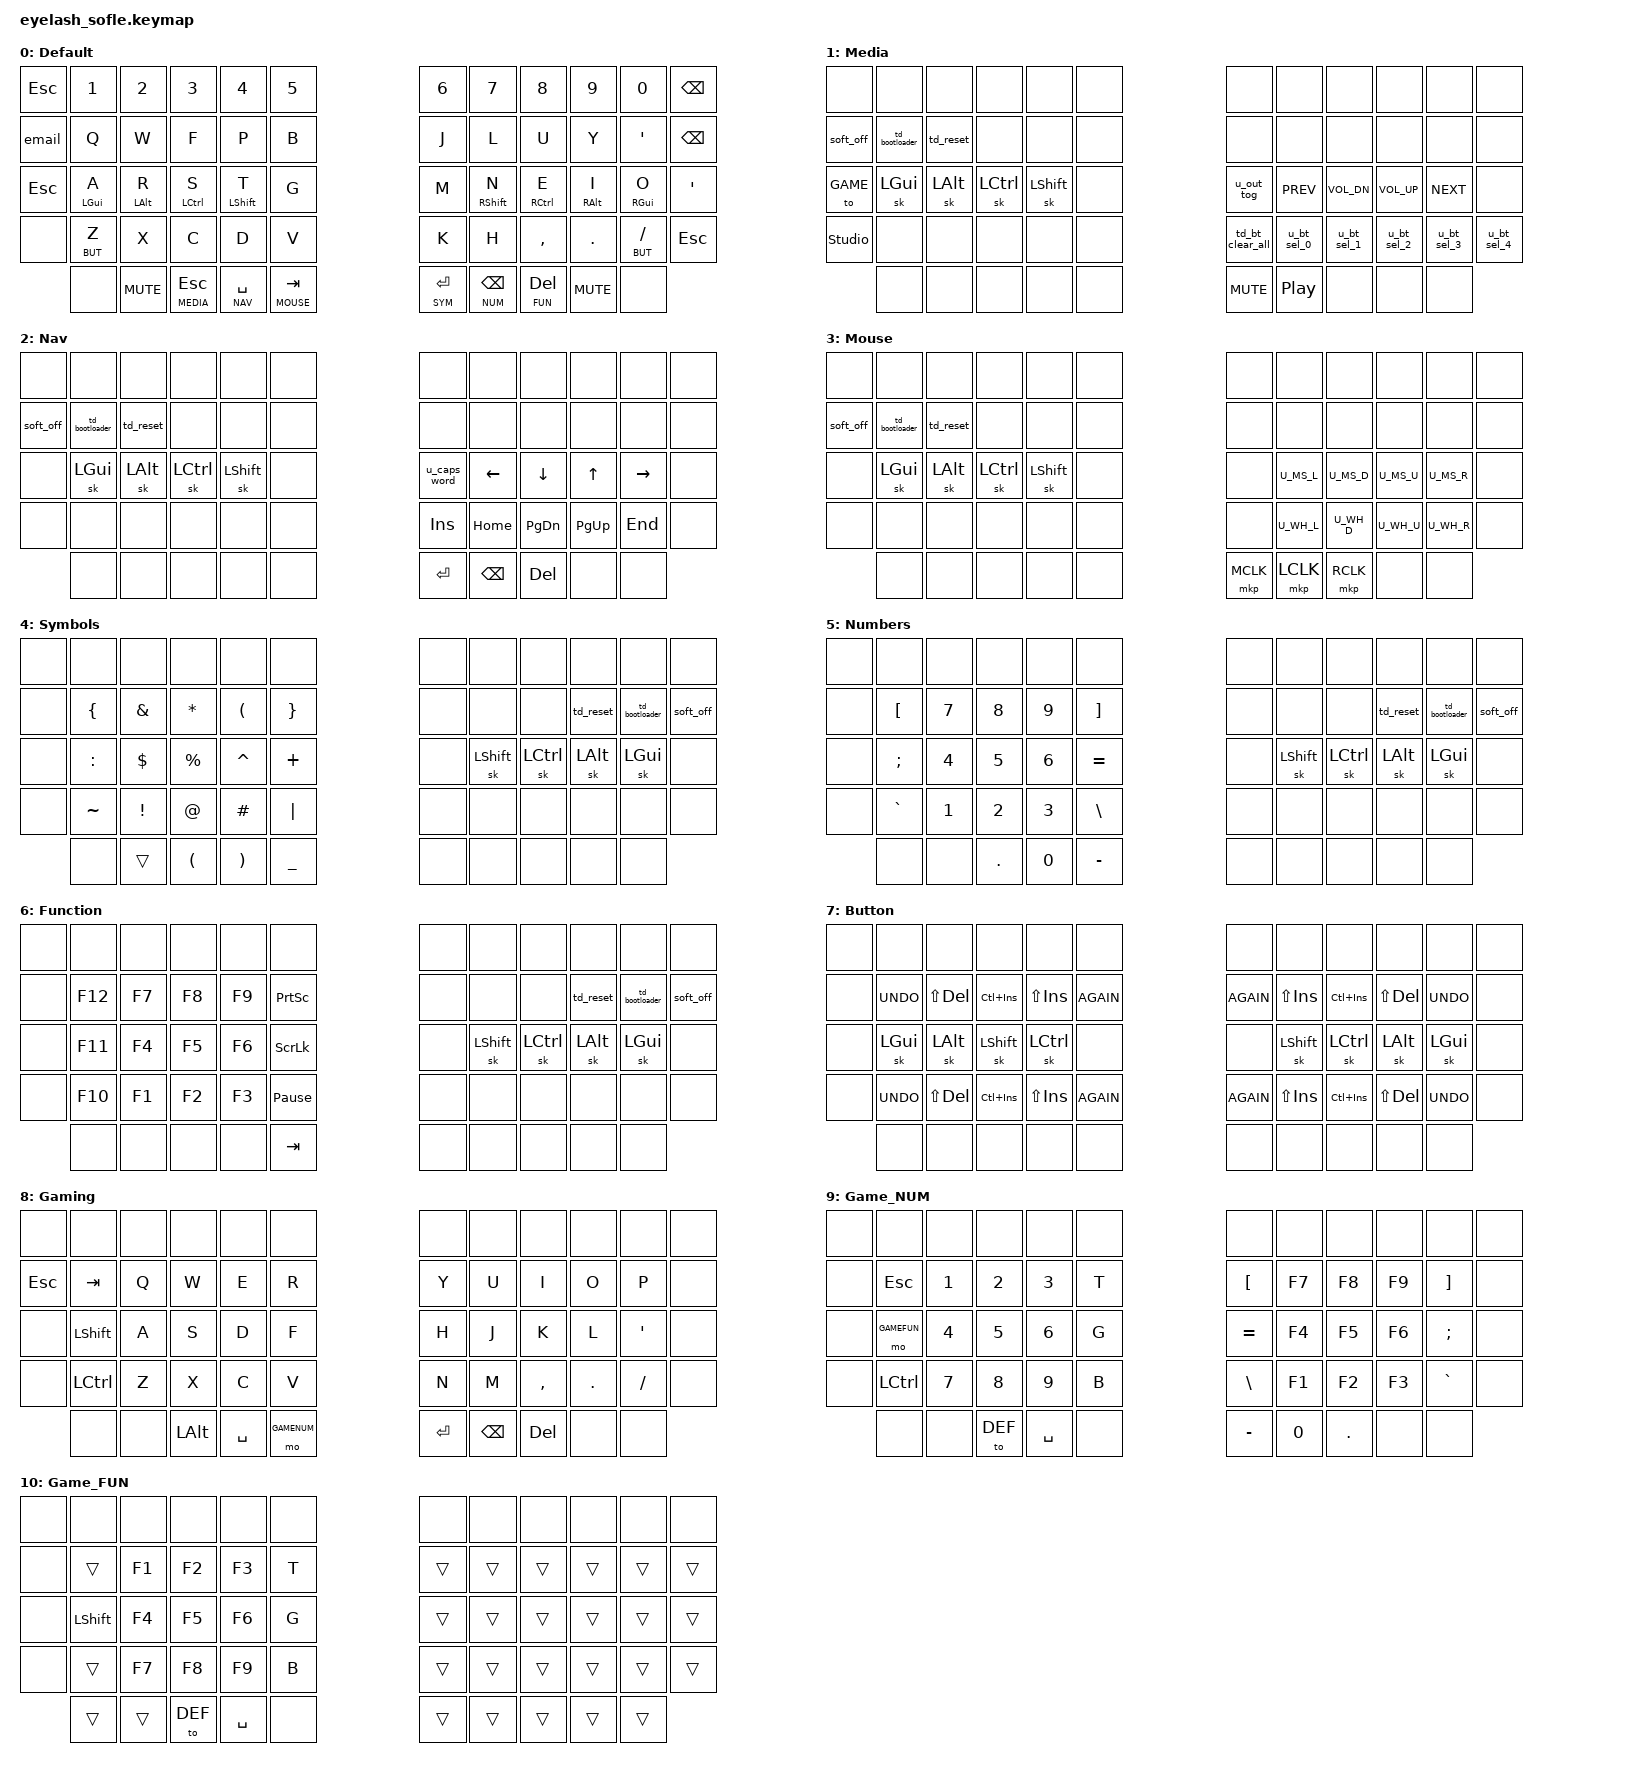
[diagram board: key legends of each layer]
//Personal keymap, subject to weird things, heavy use of helpers intended, and sticky keys

#include <behaviors.dtsi>
#include <dt-bindings/zmk/keys.h>
#include <dt-bindings/zmk/bt.h>
// #include <dt-bindings/zmk/outputs.h>

#include "zmk-helpers/helper.h"
#include "zmk-helpers/key-labels/sofle.h"
/*
  ╭────────────────────────────┬────────────────────────────╮ ╭─────────────────────────────┬─────────────────────────────╮
  │  0   1   2   3   4   5     │      6   7   8   9  10  11 │ │ LN5 LN4 LN3 LN2 LN1 LN0     │     RN0 RN1 RN2 RN3 RN4 RN5 │
  │ 12  13  14  15  16  17     │     18  19  20  21  22  23 │ │ LT5 LT4 LT3 LT2 LT1 LT0     │     RT0 RT1 RT2 RT3 RT4 RT5 │
  │ 24  25  26  27  28  29     │     30  31  32  33  34  35 │ │ LM5 LM4 LM3 LM2 LM1 LM0     │     RM0 RM1 RM2 RM3 RM4 RM5 │
  │ 36  37  38  39  40  41  42 │ 43  44  45  46  47  48  49 │ │ LB5 LB4 LB3 LB2 LB1 LB0 LEC │ REC RB0 RB1 RB2 RB3 RB4 RB5 │
  ╰───────╮ 50  51  52  53  54 │ 55  56  57  58  59 ╭───────╯ ╰───────╮ LH4 LH3 LH2 LH1 LH0 │ RH0 RH1 RH2 RH3 RH4 ╭───────╯
          ╰────────────────────┴────────────────────╯                 ╰─────────────────────┴─────────────────────╯         */

#define DEF 0
#define MEDIA 1
#define NAV 2
#define MOUSE 3
#define SYM 4
#define NUM 5
#define FUN 6
#define BUT 7
#define GAME 8
#define GAMENUM 9
#define GAMEFUN 10

#define XXX &none
#define ___ &trans

/* Global defaults */

#define QUICK_TAP_MS 175

&sk {
  release-after-ms = <900>;
  quick-release;
};

&sl { // Allow sticky mods to chord across sticky layers.
  ignore-modifiers;
};

&lt {
  flavor = "balanced";
  tapping-term-ms = <150>;
  quick-tap-ms = <QUICK_TAP_MS>;
};

#define KEYS_L LN0 LN1 LN2 LN3 LN4 LN5 LT0 LT1 LT2 LT3 LT4 LT5 LM0 LM1 LM2 LM3 LM4 LM5 LEC LB0 LB1 LB2 LB3 LB4 LB5
#define KEYS_R RN0 RN1 RN2 RN3 RN4 RN5 RT0 RT1 RT2 RT3 RT4 RT5 RM0 RM1 RM2 RM3 RM4 RM5 REC RB0 RB1 RB2 RB3 RB4 RB5
#define THUMBS LH4 LH3 LH2 LH1 LH0 RH0 RH1 RH2 RH3 RH4


/* Left-hand HRMs. */
ZMK_HOLD_TAP(hml,
    flavor = "balanced";
    tapping-term-ms = <170>;
    quick-tap-ms = <175>;
    require-prior-idle-ms = <90>;
    bindings = <&kp>, <&kp>;
    hold-trigger-key-positions = <KEYS_R THUMBS>;
    hold-trigger-on-release;
)

/* Right-hand HRMs. */
ZMK_HOLD_TAP(hmr,
    flavor = "balanced";
    tapping-term-ms = <170>;
    quick-tap-ms = <175>;
    require-prior-idle-ms = <90>;
    bindings = <&kp>, <&kp>;
    hold-trigger-key-positions = <KEYS_L THUMBS>;
    hold-trigger-on-release;
)
/* Combos, leader key sequences, mouse emulation */

// #include "combos.dtsi" // Must be sourced after HRM-combo hack.
// #include "leader.dtsi"
#include "mouse.dtsi"
#include "shift_functions.dtsi"
#include "custom_behaviors.dtsi"
#include "../miryoku_zmk/miryoku/miryoku_shift_functions.dtsi"
#include "../miryoku_zmk/miryoku/miryoku_kludge_tapdelay.h"

// Interesting feature, usefull for cases with hard to reach on/off switches
&soft_off {
    hold-time-ms = <2000>; // Only turn off it the key is held for 2 seconds or longer.
};


ZMK_LAYER(Default,
            //╭─────────────┬─────────────┬─────────────┬─────────────┬─────────────┬─────────────╮                      ╭─────────────┬─────────────┬─────────────┬─────────────┬─────────────┬─────────────╮
               &kp ESC       &kp N1        &kp N2        &kp N3        &kp N4        &kp N5                               &kp N6        &kp N7        &kp N8        &kp N9        &kp N0        &kp BSPC
            //├─────────────┼─────────────┼─────────────┼─────────────┼─────────────┼─────────────┤                      ├─────────────┼─────────────┼─────────────┼─────────────┼─────────────┼─────────────┤
               &email        &kp Q         &kp W          &kp F        &kp P         &kp B                                &kp J         &kp L         &kp U         &kp Y         &kp SQT       &kp BSPC
            //├─────────────┼─────────────┼─────────────┼─────────────┼─────────────┼─────────────┤                      ├─────────────┼─────────────┼─────────────┼─────────────┼─────────────┼─────────────┤
               &kp ESC       &hml LGUI A   &hml LALT R   &hml LCTRL S  &hml LSHFT T  &kp G                                &kp M         &hmr RSHFT N  &hmr RCTRL E  &hmr RALT I   &hmr RGUI O   &kp SQT
            //├─────────────┼─────────────┼─────────────┼─────────────┼─────────────┼─────────────┤                      ├─────────────┼─────────────┼─────────────┼─────────────┼─────────────┼─────────────┤
               XXX           &lt BUT Z     &kp X         &kp C         &kp D         &kp V                                &kp K         &kp H         &kp COMMA     &kp DOT       &lt BUT FSLH  &kp ESC
            //╰─────────────┼─────────────┼─────────────┼─────────────┼─────────────┼─────────────┤                      ├─────────────┼─────────────┼─────────────┼─────────────┼─────────────┼─────────────╯
                             XXX           &kp C_MUTE    &lt MEDIA ESC &lt NAV SPACE &lt MOUSE TAB                        &lt SYM RET   &lt NUM BSPC  &lt FUN DEL   &kp C_MUTE    XXX
            //              ╰─────────────┴─────────────┴─────────────┴─────────────┴─────────────╯                      ╰─────────────┴─────────────┴─────────────┴─────────────┴─────────────╯
)

ZMK_LAYER(Media,
            //╭─────────────┬─────────────┬─────────────┬─────────────┬─────────────┬─────────────╮                      ╭─────────────┬─────────────┬─────────────┬─────────────┬─────────────┬─────────────╮
               XXX           XXX           XXX           XXX           XXX           XXX                                  XXX           XXX           XXX           XXX           XXX           XXX
            //├─────────────┼─────────────┼─────────────┼─────────────┼─────────────┼─────────────┤                      ├─────────────┼─────────────┼─────────────┼─────────────┼─────────────┼─────────────┤
               &soft_off     &td_bootloader &td_reset    XXX           XXX           XXX                                  XXX           XXX           XXX           XXX           XXX           XXX
            //├─────────────┼─────────────┼─────────────┼─────────────┼─────────────┼─────────────┤                      ├─────────────┼─────────────┼─────────────┼─────────────┼─────────────┼─────────────┤
               &to GAME      &sk LGUI      &sk LALT      &sk LCTRL     &sk LSHFT     XXX                                  &u_out_tog    &kp C_PREV    &kp C_VOL_DN  &kp C_VOL_UP  &kp C_NEXT    XXX
            //├─────────────┼─────────────┼─────────────┼─────────────┼─────────────┼─────────────┤                      ├─────────────┼─────────────┼─────────────┼─────────────┼─────────────┼─────────────┤
               &studio_unlock XXX          XXX           XXX           XXX           XXX                                  &td_bt_clear_all &u_bt_sel_0 &u_bt_sel_1  &u_bt_sel_2   &u_bt_sel_3   &u_bt_sel_4
            //╰─────────────┼─────────────┼─────────────┼─────────────┼─────────────┼─────────────┤                      ├─────────────┼─────────────┼─────────────┼─────────────┼─────────────┼─────────────╯
                             XXX           XXX           XXX           XXX           XXX                                  &kp C_MUTE    &kp C_PP      XXX           XXX           XXX
            //              ╰─────────────┴─────────────┴─────────────┴─────────────┴─────────────╯                      ╰─────────────┴─────────────┴─────────────┴─────────────┴─────────────╯
)
ZMK_LAYER(Nav,
            //╭─────────────┬─────────────┬─────────────┬─────────────┬─────────────┬─────────────╮                      ╭─────────────┬─────────────┬─────────────┬─────────────┬─────────────┬─────────────╮
               XXX           XXX           XXX           XXX           XXX           XXX                                  XXX           XXX           XXX           XXX           XXX           XXX
            //├─────────────┼─────────────┼─────────────┼─────────────┼─────────────┼─────────────┤                      ├─────────────┼─────────────┼─────────────┼─────────────┼─────────────┼─────────────┤
               &soft_off     &td_bootloader &td_reset    XXX           XXX           XXX                                  XXX           XXX           XXX           XXX           XXX           XXX
            //├─────────────┼─────────────┼─────────────┼─────────────┼─────────────┼─────────────┤                      ├─────────────┼─────────────┼─────────────┼─────────────┼─────────────┼─────────────┤
                XXX          &sk LGUI      &sk LALT      &sk LCTRL     &sk LSHFT     XXX                                  &u_caps_word  &kp LEFT      &kp DOWN      &kp UP        &kp RIGHT     XXX
            //├─────────────┼─────────────┼─────────────┼─────────────┼─────────────┼─────────────┤                      ├─────────────┼─────────────┼─────────────┼─────────────┼─────────────┼─────────────┤
                XXX          XXX           XXX           XXX           XXX           XXX                                  &kp INS       &kp HOME      &kp PG_DN     &kp PG_UP     &kp END       XXX
            //╰─────────────┼─────────────┼─────────────┼─────────────┼─────────────┼─────────────┤                      ├─────────────┼─────────────┼─────────────┼─────────────┼─────────────┼─────────────╯
                             XXX           XXX           XXX           XXX           XXX                                  &kp RET       &kp BSPC      &kp DEL       XXX           XXX
            //              ╰─────────────┴─────────────┴─────────────┴─────────────┴─────────────╯                      ╰─────────────┴─────────────┴─────────────┴─────────────┴─────────────╯

)
ZMK_LAYER(Mouse,
            //╭─────────────┬─────────────┬─────────────┬─────────────┬─────────────┬─────────────╮                      ╭─────────────┬─────────────┬─────────────┬─────────────┬─────────────┬─────────────╮
               XXX           XXX           XXX           XXX           XXX           XXX                                  XXX           XXX           XXX           XXX           XXX           XXX
            //├─────────────┼─────────────┼─────────────┼─────────────┼─────────────┼─────────────┤                      ├─────────────┼─────────────┼─────────────┼─────────────┼─────────────┼─────────────┤
               &soft_off     &td_bootloader &td_reset    XXX           XXX           XXX                                  XXX           XXX           XXX           XXX           XXX           XXX
            //├─────────────┼─────────────┼─────────────┼─────────────┼─────────────┼─────────────┤                      ├─────────────┼─────────────┼─────────────┼─────────────┼─────────────┼─────────────┤
                XXX          &sk LGUI      &sk LALT      &sk LCTRL     &sk LSHFT     XXX                                  XXX           U_MS_L        U_MS_D        U_MS_U        U_MS_R        XXX
            //├─────────────┼─────────────┼─────────────┼─────────────┼─────────────┼─────────────┤                      ├─────────────┼─────────────┼─────────────┼─────────────┼─────────────┼─────────────┤
                XXX          XXX           XXX           XXX           XXX           XXX                                  XXX           U_WH_L        U_WH_D        U_WH_U        U_WH_R        XXX
            //╰─────────────┼─────────────┼─────────────┼─────────────┼─────────────┼─────────────┤                      ├─────────────┼─────────────┼─────────────┼─────────────┼─────────────┼─────────────╯
                             XXX           XXX           XXX           XXX           XXX                                  &mkp MCLK     &mkp LCLK     &mkp RCLK     XXX           XXX
            //              ╰─────────────┴─────────────┴─────────────┴─────────────┴─────────────╯                      ╰─────────────┴─────────────┴─────────────┴─────────────┴─────────────╯
)
ZMK_LAYER(Symbols,
            //╭─────────────┬─────────────┬─────────────┬─────────────┬─────────────┬─────────────╮                      ╭─────────────┬─────────────┬─────────────┬─────────────┬─────────────┬─────────────╮
               XXX           XXX           XXX           XXX           XXX           XXX                                  XXX           XXX           XXX           XXX           XXX           XXX
            //├─────────────┼─────────────┼─────────────┼─────────────┼─────────────┼─────────────┤                      ├─────────────┼─────────────┼─────────────┼─────────────┼─────────────┼─────────────┤
                XXX          &kp LBRC      &kp AMPERSAND &kp ASTERISK  &kp LPAR      &kp RBRC                             XXX           XXX           XXX           &td_reset     &td_bootloader &soft_off
            //├─────────────┼─────────────┼─────────────┼─────────────┼─────────────┼─────────────┤                      ├─────────────┼─────────────┼─────────────┼─────────────┼─────────────┼─────────────┤
                XXX          &kp COLON     &kp DOLLAR    &kp PRCNT     &kp CARET     &kp PLUS                             XXX           &sk LSHFT     &sk LCTRL     &sk LALT      &sk LGUI      XXX
            //├─────────────┼─────────────┼─────────────┼─────────────┼─────────────┼─────────────┤                      ├─────────────┼─────────────┼─────────────┼─────────────┼─────────────┼─────────────┤
                XXX          &kp TILDE     &kp EXCL      &kp AT        &kp HASH      &kp PIPE                             XXX           XXX           XXX           XXX           XXX           XXX
            //╰─────────────┼─────────────┼─────────────┼─────────────┼─────────────┼─────────────┤                      ├─────────────┼─────────────┼─────────────┼─────────────┼─────────────┼─────────────╯
                             XXX           ___           &kp LPAR      &kp RPAR      &kp UNDER                            XXX           XXX           XXX           XXX           XXX
            //              ╰─────────────┴─────────────┴─────────────┴─────────────┴─────────────╯                      ╰─────────────┴─────────────┴─────────────┴─────────────┴─────────────╯
)
ZMK_LAYER(Numbers,
            //╭─────────────┬─────────────┬─────────────┬─────────────┬─────────────┬─────────────╮                      ╭─────────────┬─────────────┬─────────────┬─────────────┬─────────────┬─────────────╮
               XXX           XXX           XXX           XXX           XXX           XXX                                  XXX           XXX           XXX           XXX           XXX           XXX
            //├─────────────┼─────────────┼─────────────┼─────────────┼─────────────┼─────────────┤                      ├─────────────┼─────────────┼─────────────┼─────────────┼─────────────┼─────────────┤
                XXX          &kp LBKT      &kp N7        &kp N8       &kp N9        &kp RBKT                             XXX           XXX           XXX           &td_reset     &td_bootloader &soft_off
            //├─────────────┼─────────────┼─────────────┼─────────────┼─────────────┼─────────────┤                      ├─────────────┼─────────────┼─────────────┼─────────────┼─────────────┼─────────────┤
                XXX          &kp SEMICOLON &kp N4         &kp N5       &kp N6        &kp EQUAL                            XXX           &sk LSHFT     &sk LCTRL     &sk LALT      &sk LGUI      XXX
            //├─────────────┼─────────────┼─────────────┼─────────────┼─────────────┼─────────────┤                      ├─────────────┼─────────────┼─────────────┼─────────────┼─────────────┼─────────────┤
                XXX          &kp GRAVE     &kp N1         &kp N2       &kp N3        &kp BSLH                             XXX           XXX           XXX           XXX           XXX           XXX
            //╰─────────────┼─────────────┼─────────────┼─────────────┼─────────────┼─────────────┤                      ├─────────────┼─────────────┼─────────────┼─────────────┼─────────────┼─────────────╯
                             XXX           XXX           &kp DOT       &kp N0        &kp MINUS                            XXX           XXX           XXX           XXX           XXX
            //              ╰─────────────┴─────────────┴─────────────┴─────────────┴─────────────╯                      ╰─────────────┴─────────────┴─────────────┴─────────────┴─────────────╯
)
ZMK_LAYER(Function,
            //╭─────────────┬─────────────┬─────────────┬─────────────┬─────────────┬─────────────╮                      ╭─────────────┬─────────────┬─────────────┬─────────────┬─────────────┬─────────────╮
               XXX           XXX           XXX           XXX           XXX           XXX                                  XXX           XXX           XXX           XXX           XXX           XXX
            //├─────────────┼─────────────┼─────────────┼─────────────┼─────────────┼─────────────┤                      ├─────────────┼─────────────┼─────────────┼─────────────┼─────────────┼─────────────┤
               XXX           &kp F12       &kp F7        &kp F8        &kp F9        &kp PSCRN                            XXX           XXX           XXX           &td_reset     &td_bootloader &soft_off
            //├─────────────┼─────────────┼─────────────┼─────────────┼─────────────┼─────────────┤                      ├─────────────┼─────────────┼─────────────┼─────────────┼─────────────┼─────────────┤
               XXX           &kp F11       &kp F4        &kp F5        &kp F6        &kp SLCK                             XXX           &sk LSHFT     &sk LCTRL     &sk LALT      &sk LGUI      XXX
            //├─────────────┼─────────────┼─────────────┼─────────────┼─────────────┼─────────────┤                      ├─────────────┼─────────────┼─────────────┼─────────────┼─────────────┼─────────────┤
               XXX           &kp F10       &kp F1        &kp F2        &kp F3        &kp PAUSE_BREAK                      XXX           XXX           XXX           XXX           XXX           XXX
            //╰─────────────┼─────────────┼─────────────┼─────────────┼─────────────┼─────────────┤                      ├─────────────┼─────────────┼─────────────┼─────────────┼─────────────┼─────────────╯
                             XXX           XXX           XXX           XXX           &kp TAB                              XXX           XXX           XXX           XXX           XXX
            //              ╰─────────────┴─────────────┴─────────────┴─────────────┴─────────────╯                      ╰─────────────┴─────────────┴─────────────┴─────────────┴─────────────╯
)
ZMK_LAYER(Button,
            //╭─────────────┬─────────────┬─────────────┬─────────────┬─────────────┬─────────────╮                      ╭─────────────┬─────────────┬─────────────┬─────────────┬─────────────┬─────────────╮
               XXX           XXX           XXX           XXX           XXX           XXX                                  XXX           XXX           XXX           XXX           XXX           XXX
            //├─────────────┼─────────────┼─────────────┼─────────────┼─────────────┼─────────────┤                      ├─────────────┼─────────────┼─────────────┼─────────────┼─────────────┼─────────────┤
               XXX           &kp K_UNDO    &kp LS(DEL)   &kp LC(INS)   &kp LS(INS)   &kp K_AGAIN                          &kp K_AGAIN   &kp LS(INS)   &kp LC(INS)   &kp LS(DEL)   &kp K_UNDO    XXX
            //├─────────────┼─────────────┼─────────────┼─────────────┼─────────────┼─────────────┤                      ├─────────────┼─────────────┼─────────────┼─────────────┼─────────────┼─────────────┤
               XXX           &sk LGUI      &sk LALT      &sk LSHFT     &sk LCTRL     XXX                                  XXX           &sk LSHFT     &sk LCTRL     &sk LALT      &sk LGUI      XXX
            //├─────────────┼─────────────┼─────────────┼─────────────┼─────────────┼─────────────┤                      ├─────────────┼─────────────┼─────────────┼─────────────┼─────────────┼─────────────┤
               XXX           &kp K_UNDO    &kp LS(DEL)   &kp LC(INS)   &kp LS(INS)   &kp K_AGAIN                          &kp K_AGAIN   &kp LS(INS)   &kp LC(INS)   &kp LS(DEL)   &kp K_UNDO    XXX
            //╰─────────────┼─────────────┼─────────────┼─────────────┼─────────────┼─────────────┤                      ├─────────────┼─────────────┼─────────────┼─────────────┼─────────────┼─────────────╯
                             XXX           XXX           XXX           XXX           XXX                                  XXX           XXX           XXX           XXX           XXX
            //              ╰─────────────┴─────────────┴─────────────┴─────────────┴─────────────╯                      ╰─────────────┴─────────────┴─────────────┴─────────────┴─────────────╯
)
ZMK_LAYER(Gaming,
            //╭─────────────┬─────────────┬─────────────┬─────────────┬─────────────┬─────────────╮                      ╭─────────────┬─────────────┬─────────────┬─────────────┬─────────────┬─────────────╮
               XXX           XXX           XXX           XXX           XXX           XXX                                  XXX           XXX           XXX           XXX           XXX           XXX
            //├─────────────┼─────────────┼─────────────┼─────────────┼─────────────┼─────────────┤                      ├─────────────┼─────────────┼─────────────┼─────────────┼─────────────┼─────────────┤
               &kp ESC       &kp TAB       &kp Q         &kp W         &kp E         &kp R                                &kp Y         &kp U         &kp I         &kp O         &kp P         XXX
            //├─────────────┼─────────────┼─────────────┼─────────────┼─────────────┼─────────────┤                      ├─────────────┼─────────────┼─────────────┼─────────────┼─────────────┼─────────────┤
               XXX           &kp LSHFT     &kp A         &kp S         &kp D         &kp F                                &kp H         &kp J         &kp K         &kp L         &kp SQT       XXX
            //├─────────────┼─────────────┼─────────────┼─────────────┼─────────────┼─────────────┤                      ├─────────────┼─────────────┼─────────────┼─────────────┼─────────────┼─────────────┤
               XXX           &kp LCTRL     &kp Z         &kp X         &kp C         &kp V                                &kp N         &kp M         &kp COMMA     &kp DOT       &kp FSLH      XXX
            //╰─────────────┼─────────────┼─────────────┼─────────────┼─────────────┼─────────────┤                      ├─────────────┼─────────────┼─────────────┼─────────────┼─────────────┼─────────────╯
                             XXX           XXX           &kp LALT      &kp SPACE     &mo GAMENUM                          &kp RET       &kp BSPC      &kp DEL       XXX           XXX
            //              ╰─────────────┴─────────────┴─────────────┴─────────────┴─────────────╯                      ╰─────────────┴─────────────┴─────────────┴─────────────┴─────────────╯
)
ZMK_LAYER(Game_NUM,
            //╭─────────────┬─────────────┬─────────────┬─────────────┬─────────────┬─────────────╮                      ╭─────────────┬─────────────┬─────────────┬─────────────┬─────────────┬─────────────╮
               XXX           XXX           XXX           XXX           XXX           XXX                                  XXX           XXX           XXX           XXX           XXX           XXX
            //├─────────────┼─────────────┼─────────────┼─────────────┼─────────────┼─────────────┤                      ├─────────────┼─────────────┼─────────────┼─────────────┼─────────────┼─────────────┤
               XXX           &kp ESC       &kp N1        &kp N2        &kp N3        &kp T                                &kp LBKT      &kp F7        &kp F8        &kp F9        &kp RBKT      XXX
            //├─────────────┼─────────────┼─────────────┼─────────────┼─────────────┼─────────────┤                      ├─────────────┼─────────────┼─────────────┼─────────────┼─────────────┼─────────────┤
               XXX           &mo GAMEFUN   &kp N4        &kp N5        &kp N6        &kp G                                &kp EQUAL     &kp F4        &kp F5        &kp F6        &kp SEMICOLON XXX
            //├─────────────┼─────────────┼─────────────┼─────────────┼─────────────┼─────────────┤                      ├─────────────┼─────────────┼─────────────┼─────────────┼─────────────┼─────────────┤
               XXX           &kp LCTRL     &kp N7        &kp N8        &kp N9        &kp B                                &kp BSLH      &kp F1        &kp F2        &kp F3        &kp GRAVE     XXX
            //╰─────────────┼─────────────┼─────────────┼─────────────┼─────────────┼─────────────┤                      ├─────────────┼─────────────┼─────────────┼─────────────┼─────────────┼─────────────╯
                             XXX           XXX           &to DEF       &kp SPACE     XXX                                  &kp MINUS     &kp N0        &kp DOT       XXX           XXX
            //              ╰─────────────┴─────────────┴─────────────┴─────────────┴─────────────╯                      ╰─────────────┴─────────────┴─────────────┴─────────────┴─────────────╯
)
ZMK_LAYER(Game_FUN,
            //╭─────────────┬─────────────┬─────────────┬─────────────┬─────────────┬─────────────╮                      ╭─────────────┬─────────────┬─────────────┬─────────────┬─────────────┬─────────────╮
               XXX           XXX           XXX           XXX           XXX           XXX                                  XXX           XXX           XXX           XXX           XXX           XXX
            //├─────────────┼─────────────┼─────────────┼─────────────┼─────────────┼─────────────┤                      ├─────────────┼─────────────┼─────────────┼─────────────┼─────────────┼─────────────┤
               XXX           ___           &kp F1        &kp F2        &kp F3        &kp T                                ___           ___           ___           ___           ___           ___
            //├─────────────┼─────────────┼─────────────┼─────────────┼─────────────┼─────────────┤                      ├─────────────┼─────────────┼─────────────┼─────────────┼─────────────┼─────────────┤
               XXX           &kp LSHFT     &kp F4        &kp F5        &kp F6        &kp G                                ___           ___           ___           ___           ___           ___
            //├─────────────┼─────────────┼─────────────┼─────────────┼─────────────┼─────────────┤                      ├─────────────┼─────────────┼─────────────┼─────────────┼─────────────┼─────────────┤
               XXX           ___           &kp F7        &kp F8        &kp F9        &kp B                                ___           ___           ___           ___           ___           ___
            //╰─────────────┼─────────────┼─────────────┼─────────────┼─────────────┼─────────────┤                      ├─────────────┼─────────────┼─────────────┼─────────────┼─────────────┼─────────────╯
                             ___           ___           &to DEF       &kp SPACE     XXX                                  ___           ___           ___           ___           ___
            //              ╰─────────────┴─────────────┴─────────────┴─────────────┴─────────────╯                      ╰─────────────┴─────────────┴─────────────┴─────────────┴─────────────╯
)



//              >;
//         };
//         lower_layer {
//             // -----------------------------------------------------------------------------------------
//             // |  TAB |  1  |  2  |  3  |  4  |  5  |                 |  6  |  7  |  8  |  9  |  0  | BKSP |
//             // | BTCLR| BT1 | BT2 | BT3 | BT4 | BT5 |                 | LFT | DWN |  UP | RGT |     |      |
//             // | SHFT |     |     |     |     |     | MUTE |   | MUTE |     |     |     |     |     |      |
//             //                     MUTE | GUI |     | SPC  |   |  ENT |     | ALT | MUTE
//             bindings = <
//                 &kp TAB    &kp N1       &kp N2       &kp N3       &kp N4       &kp N5                             &kp N6   &kp N7   &kp N8     &kp N9    &kp N0 &kp BSPC
//                 &bt BT_CLR &bt BT_SEL 0 &bt BT_SEL 1 &bt BT_SEL 2 &bt BT_SEL 3 &bt BT_SEL 4                       XXX      &kp LEFT &kp DOWN &kp UP     &kp RIGHT &trans
//                 &kp LSHFT  &studio_unlock       &trans       &trans       &trans       &trans       &kp C_MUTE &kp C_MUTE &trans   &trans   &trans     &trans    &trans &trans
//                                                      &kp C_MUTE   &kp LGUI     &trans       &kp SPACE  &kp RET    &trans   &kp RALT &kp C_MUTE
//                                                      &kp UP                                                                         &kp UP
//                                             &kp LEFT &sk LGUI  &kp RIGHT                                                  &kp LEFT  &kp SPACE  &kp RIGHT
//                                                      &kp DOWN                                                                       &kp DOWN
//
//             >;
//             sensor-bindings = <
//                 &inc_dec_kp C_VOL_UP C_VOL_DN
//                 &inc_dec_kp C_VOL_UP C_VOL_DN
//                 &inc_dec_kp C_VOL_UP C_VOL_DN
//                 &inc_dec_kp C_VOL_UP C_VOL_DN
//
//              >;
//         };
//
//         raise_layer {
//             // -----------------------------------------------------------------------------------------
//             // |  TAB |  !  |  @  |  #  |  $  |  %  |                 |  ^  |  &  |  *  |  (  |  )  | BKSP |
//             // | CTRL |     |     |     |     |     |                 |  -  |  =  |  [  |  ]  |  \  |  `   |
//             // | SHFT |     |     |     |     |     | MUTE |   | MUTE |  _  |  +  |  {  |  }  | "|" |  ~   |
//             //                     MUTE | GUI |     | SPC |     | ENT |     | ALT | MUTE
//             bindings = <
//                 &kp  TAB  &kp EXCL &kp AT &kp HASH   &kp DLLR &kp PRCNT                         &kp CARET &kp AMPS  &kp ASTRK &kp LPAR &kp RPAR &kp BSPC
//                 &kp LCTRL &trans   &trans &trans     &trans   &trans                            &kp MINUS &kp EQUAL &kp LBKT  &kp RBKT &kp BSLH &kp GRAVE
//                 &kp LSHFT &trans   &trans &trans     &trans   &trans    &kp C_MUTE  &kp C_MUTE  &kp UNDER &kp PLUS  &kp LBRC  &kp RBRC &kp PIPE &kp TILDE
//                                           &kp C_MUTE &kp LGUI &trans    &kp SPACE   &kp RET     &trans    &kp RALT  &kp C_MUTE
//                                           &kp UP                                                                    &kp UP
//                                  &kp LEFT &sk LGUI  &kp RIGHT                                             &kp LEFT  &kp SPACE  &kp RIGHT
//                                           &kp DOWN                                                                  &kp DOWN
//
//             >;
//             sensor-bindings = <
//                 &inc_dec_kp C_VOL_UP C_VOL_DN
//                 &inc_dec_kp C_VOL_UP C_VOL_DN
//                 &inc_dec_kp C_VOL_UP C_VOL_DN
//                 &inc_dec_kp C_VOL_UP C_VOL_DN
//
//              >;
//         };
//     };
// };
//




